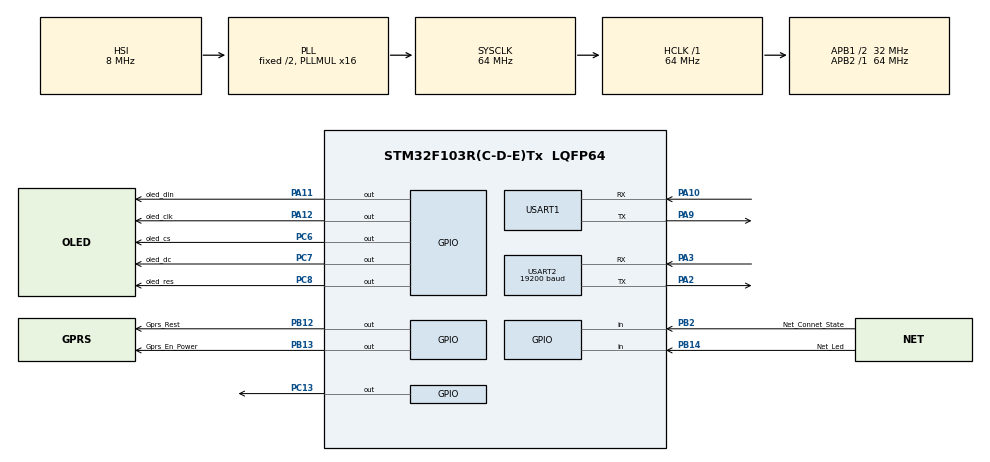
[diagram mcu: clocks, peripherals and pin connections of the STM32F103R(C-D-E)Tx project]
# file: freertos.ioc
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Dma.Request0=USART2_RX
Dma.Request1=USART2_TX
Dma.Request2=USART1_RX
Dma.Request3=USART1_TX
Dma.USART1_RX.2.Direction=DMA_PERIPH_TO_MEMORY
Dma.USART1_RX.2.Instance=DMA1_Channel5
Dma.USART1_RX.2.MemDataAlignment=DMA_MDATAALIGN_BYTE
Dma.USART1_RX.2.MemInc=DMA_MINC_ENABLE
Dma.USART1_RX.2.Mode=DMA_CIRCULAR
Dma.USART1_RX.2.PeriphDataAlignment=DMA_PDATAALIGN_BYTE
Dma.USART1_RX.2.PeriphInc=DMA_PINC_DISABLE
Dma.USART1_RX.2.Priority=DMA_PRIORITY_LOW
Dma.USART1_TX.3.Direction=DMA_MEMORY_TO_PERIPH
Dma.USART1_TX.3.Instance=DMA1_Channel4
Dma.USART1_TX.3.MemDataAlignment=DMA_MDATAALIGN_BYTE
Dma.USART1_TX.3.MemInc=DMA_MINC_ENABLE
Dma.USART1_TX.3.Mode=DMA_NORMAL
Dma.USART1_TX.3.PeriphDataAlignment=DMA_PDATAALIGN_BYTE
Dma.USART1_TX.3.PeriphInc=DMA_PINC_DISABLE
Dma.USART1_TX.3.Priority=DMA_PRIORITY_LOW
Dma.USART2_RX.0.Direction=DMA_PERIPH_TO_MEMORY
Dma.USART2_RX.0.Instance=DMA1_Channel6
Dma.USART2_RX.0.MemDataAlignment=DMA_MDATAALIGN_BYTE
Dma.USART2_RX.0.MemInc=DMA_MINC_ENABLE
Dma.USART2_RX.0.Mode=DMA_CIRCULAR
Dma.USART2_RX.0.PeriphDataAlignment=DMA_PDATAALIGN_BYTE
Dma.USART2_RX.0.PeriphInc=DMA_PINC_DISABLE
Dma.USART2_RX.0.Priority=DMA_PRIORITY_LOW
Dma.USART2_TX.1.Direction=DMA_MEMORY_TO_PERIPH
Dma.USART2_TX.1.Instance=DMA1_Channel7
Dma.USART2_TX.1.MemDataAlignment=DMA_MDATAALIGN_BYTE
Dma.USART2_TX.1.MemInc=DMA_MINC_ENABLE
Dma.USART2_TX.1.Mode=DMA_NORMAL
Dma.USART2_TX.1.PeriphDataAlignment=DMA_PDATAALIGN_BYTE
Dma.USART2_TX.1.PeriphInc=DMA_PINC_DISABLE
Dma.USART2_TX.1.Priority=DMA_PRIORITY_LOW
FREERTOS.Queues01=myQueue01,16,uint16_t,NULL,Dynamic,NULL,NULL
FREERTOS.Tasks01=defaultTask,0,128,StartDefaultTask,Default,NULL,Dynamic,NULL,NULL
FREERTOS.Timers01=myTimer01,Callback01,osTimerPeriodic,Default,NULL,Dynamic,NULL
FREERTOS.configUSE_TIMERS=1
Mcu.Family=STM32F1
Mcu.Name=STM32F103R(C-D-E)Tx
Mcu.Package=LQFP64
NVIC.DMA1_Channel4_IRQn=true\:5\:0\:false\:false\:true\:true
NVIC.DMA1_Channel5_IRQn=true\:5\:0\:false\:false\:true\:true
NVIC.DMA1_Channel6_IRQn=true\:5\:0\:true\:false\:true\:true
NVIC.DMA1_Channel7_IRQn=true\:5\:0\:true\:false\:true\:true
NVIC.PriorityGroup=NVIC_PRIORITYGROUP_4
NVIC.USART1_IRQn=true\:5\:0\:false\:false\:true\:true
NVIC.USART2_IRQn=true\:5\:0\:false\:false\:true\:true
PA10.Mode=Asynchronous
PA10.Signal=USART1_RX
PA11.GPIO_Label=oled_din
PA11.Signal=GPIO_Output
PA12.GPIO_Label=oled_clk
PA12.Signal=GPIO_Output
PA13.Mode=Serial_Wire
PA13.Signal=SYS_JTMS-SWDIO
PA14.Mode=Serial_Wire
PA14.Signal=SYS_JTCK-SWCLK
PA2.Mode=Asynchronous
PA2.Signal=USART2_TX
PA3.Mode=Asynchronous
PA3.Signal=USART2_RX
PA9.Mode=Asynchronous
PA9.Signal=USART1_TX
PB12.GPIO_Label=Gprs_Rest
PB12.Signal=GPIO_Output
PB13.GPIO_Label=Gprs_En_Power
PB13.Signal=GPIO_Output
PB14.GPIO_Label=Net_Led
PB14.GPIO_PuPd=GPIO_PULLUP
PB14.Signal=GPIO_Input
PB2.GPIO_Label=Net_Connet_State
PB2.Signal=GPIO_Input
PC13-TAMPER-RTC.Signal=GPIO_Output
PC6.GPIO_Label=oled_cs
PC6.PinState=GPIO_PIN_SET
PC6.Signal=GPIO_Output
PC7.GPIO_Label=oled_dc
PC7.Signal=GPIO_Output
PC8.GPIO_Label=oled_res
PC8.Signal=GPIO_Output
ProjectManager.HeapSize=0x200
ProjectManager.StackSize=0x400
ProjectManager.TargetToolchain=MDK-ARM V5
RCC.AHBFreq_Value=64000000
RCC.APB1CLKDivider=RCC_HCLK_DIV2
RCC.APB1Freq_Value=32000000
RCC.APB1TimFreq_Value=64000000
RCC.APB2Freq_Value=64000000
RCC.APB2TimFreq_Value=64000000
RCC.HCLKFreq_Value=64000000
RCC.PLLMUL=RCC_PLL_MUL16
RCC.SYSCLKFreq_VALUE=64000000
RCC.SYSCLKSource=RCC_SYSCLKSOURCE_PLLCLK
RCC.USBFreq_Value=64000000
USART1.VirtualMode=VM_ASYNC
USART2.BaudRate=19200
USART2.VirtualMode=VM_ASYNC
VP_FREERTOS_VS_ENABLE.Mode=Enabled
board=freertos

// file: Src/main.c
/**
  ******************************************************************************
  * File Name          : main.c
  * Description        : Main program body
  ******************************************************************************
  * This notice applies to any and all portions of this file
  * that are not between comment pairs USER CODE BEGIN and
  * USER CODE END. Other portions of this file, whether
  * inserted by the user or by software development tools
  * are owned by their respective copyright owners.
  *
  * Copyright (c) 2017 STMicroelectronics International N.V.
  * All rights reserved.
  *
  * Redistribution and use in source and binary forms, with or without
  * modification, are permitted, provided that the following conditions are met:
  *
  * 1. Redistribution of source code must retain the above copyright notice,
  *    this list of conditions and the following disclaimer.
  * 2. Redistributions in binary form must reproduce the above copyright notice,
  *    this list of conditions and the following disclaimer in the documentation
  *    and/or other materials provided with the distribution.
  * 3. Neither the name of STMicroelectronics nor the names of other
  *    contributors to this software may be used to endorse or promote products
  *    derived from this software without specific written permission.
  * 4. This software, including modifications and/or derivative works of this
  *    software, must execute solely and exclusively on microcontroller or
  *    microprocessor devices manufactured by or for STMicroelectronics.
  * 5. Redistribution and use of this software other than as permitted under
  *    this license is void and will automatically terminate your rights under
  *    this license.
  *
  * THIS SOFTWARE IS PROVIDED BY STMICROELECTRONICS AND CONTRIBUTORS "AS IS"
  * AND ANY EXPRESS, IMPLIED OR STATUTORY WARRANTIES, INCLUDING, BUT NOT
  * LIMITED TO, THE IMPLIED WARRANTIES OF MERCHANTABILITY, FITNESS FOR A
  * PARTICULAR PURPOSE AND NON-INFRINGEMENT OF THIRD PARTY INTELLECTUAL PROPERTY
  * RIGHTS ARE DISCLAIMED TO THE FULLEST EXTENT PERMITTED BY LAW. IN NO EVENT
  * SHALL STMICROELECTRONICS OR CONTRIBUTORS BE LIABLE FOR ANY DIRECT, INDIRECT,
  * INCIDENTAL, SPECIAL, EXEMPLARY, OR CONSEQUENTIAL DAMAGES (INCLUDING, BUT NOT
  * LIMITED TO, PROCUREMENT OF SUBSTITUTE GOODS OR SERVICES; LOSS OF USE, DATA,
  * OR PROFITS; OR BUSINESS INTERRUPTION) HOWEVER CAUSED AND ON ANY THEORY OF
  * LIABILITY, WHETHER IN CONTRACT, STRICT LIABILITY, OR TORT (INCLUDING
  * NEGLIGENCE OR OTHERWISE) ARISING IN ANY WAY OUT OF THE USE OF THIS SOFTWARE,
  * EVEN IF ADVISED OF THE POSSIBILITY OF SUCH DAMAGE.
  *
  ******************************************************************************
  */
#include "main.h"
#include "stm32f1xx_hal.h"
#include "cmsis_os.h"

/* USER CODE BEGIN Includes */
#include "oled.h"
#include "gprs.h"
/* USER CODE END Includes */

UART_HandleTypeDef huart1;
UART_HandleTypeDef huart2;
DMA_HandleTypeDef hdma_usart1_rx;
DMA_HandleTypeDef hdma_usart1_tx;
DMA_HandleTypeDef hdma_usart2_rx;
DMA_HandleTypeDef hdma_usart2_tx;

osThreadId defaultTaskHandle;
osMessageQId myQueue01Handle;
osTimerId myTimer01Handle;

/* USER CODE BEGIN PV */
/* Private variables ---------------------------------------------------------*/
#define MAXSIZE 100
uint8_t arev_zigbee[1];
uint8_t arev_mqtt[1];
uint8_t RX_DATA[MAXSIZE]={0};
/* USER CODE END PV */

void SystemClock_Config(void);
static void MX_GPIO_Init(void);
static void MX_DMA_Init(void);
static void MX_USART2_UART_Init(void);
static void MX_USART1_UART_Init(void);
void StartDefaultTask(void const * argument);
void Callback01(void const * argument);

/* USER CODE BEGIN PFP */
/* Private function prototypes -----------------------------------------------*/

/* USER CODE END PFP */

int main(void)
{

  /* MCU Configuration----------------------------------------------------------*/

  /* Reset of all peripherals, Initializes the Flash interface and the Systick. */
  HAL_Init();

  /* Configure the system clock */
  SystemClock_Config();

  /* Initialize all configured peripherals */
  MX_GPIO_Init();
  MX_DMA_Init();
  MX_USART2_UART_Init();
  MX_USART1_UART_Init();

  /* USER CODE BEGIN 2 */
//	u8 test1[10]="haoren\r\n";
	OLED_Init();
	init_gprs();
	HAL_UART_Receive_DMA(&huart2, arev_zigbee, 1);
	HAL_UART_Receive_DMA(&huart1,RX_DATA,MAXSIZE);
	__HAL_UART_ENABLE_IT(&huart1,UART_IT_IDLE);
  //HAL_UART_Transmit_DMA(&huart1 , (u8*)"AT\r\n" ,4);
  /* USER CODE END 2 */

  /* Create the timer(s) */
  /* definition and creation of myTimer01 */
  osTimerDef(myTimer01, Callback01);
  myTimer01Handle = osTimerCreate(osTimer(myTimer01), osTimerPeriodic, NULL);

  /* Create the thread(s) */
  /* definition and creation of defaultTask */
  osThreadDef(defaultTask, StartDefaultTask, osPriorityNormal, 0, 128);
  defaultTaskHandle = osThreadCreate(osThread(defaultTask), NULL);

  /* Create the queue(s) */
  /* definition and creation of myQueue01 */
  osMessageQDef(myQueue01, 16, uint16_t);
  myQueue01Handle = osMessageCreate(osMessageQ(myQueue01), NULL);

  /* USER CODE BEGIN RTOS_QUEUES */
  /* add queues, ... */
	osTimerStart(myTimer01Handle,1000);
  /* USER CODE END RTOS_QUEUES */

  /* Start scheduler */
  osKernelStart();

  /* We should never get here as control is now taken by the scheduler */

  /* Infinite loop */

  while (1)
  {

  }

}

/** System Clock Configuration
*/
void SystemClock_Config(void)
{

  RCC_OscInitTypeDef RCC_OscInitStruct;
  RCC_ClkInitTypeDef RCC_ClkInitStruct;

    /**Initializes the CPU, AHB and APB busses clocks
    */
  RCC_OscInitStruct.OscillatorType = RCC_OSCILLATORTYPE_HSI;
  RCC_OscInitStruct.HSIState = RCC_HSI_ON;
  RCC_OscInitStruct.HSICalibrationValue = 16;
  RCC_OscInitStruct.PLL.PLLState = RCC_PLL_ON;
  RCC_OscInitStruct.PLL.PLLSource = RCC_PLLSOURCE_HSI_DIV2;
  RCC_OscInitStruct.PLL.PLLMUL = RCC_PLL_MUL16;
  if (HAL_RCC_OscConfig(&RCC_OscInitStruct) != HAL_OK)
  {
    _Error_Handler(__FILE__, __LINE__);
  }

    /**Initializes the CPU, AHB and APB busses clocks
    */
  RCC_ClkInitStruct.ClockType = RCC_CLOCKTYPE_HCLK|RCC_CLOCKTYPE_SYSCLK
                              |RCC_CLOCKTYPE_PCLK1|RCC_CLOCKTYPE_PCLK2;
  RCC_ClkInitStruct.SYSCLKSource = RCC_SYSCLKSOURCE_PLLCLK;
  RCC_ClkInitStruct.AHBCLKDivider = RCC_SYSCLK_DIV1;
  RCC_ClkInitStruct.APB1CLKDivider = RCC_HCLK_DIV2;
  RCC_ClkInitStruct.APB2CLKDivider = RCC_HCLK_DIV1;

  if (HAL_RCC_ClockConfig(&RCC_ClkInitStruct, FLASH_LATENCY_2) != HAL_OK)
  {
    _Error_Handler(__FILE__, __LINE__);
  }

    /**Configure the Systick interrupt time
    */
  HAL_SYSTICK_Config(HAL_RCC_GetHCLKFreq()/1000);

    /**Configure the Systick
    */
  HAL_SYSTICK_CLKSourceConfig(SYSTICK_CLKSOURCE_HCLK);

  /* SysTick_IRQn interrupt configuration */
  HAL_NVIC_SetPriority(SysTick_IRQn, 15, 0);
}

/* USART1 init function */
static void MX_USART1_UART_Init(void)
{

  huart1.Instance = USART1;
  huart1.Init.BaudRate = 115200;
  huart1.Init.WordLength = UART_WORDLENGTH_8B;
  huart1.Init.StopBits = UART_STOPBITS_1;
  huart1.Init.Parity = UART_PARITY_NONE;
  huart1.Init.Mode = UART_MODE_TX_RX;
  huart1.Init.HwFlowCtl = UART_HWCONTROL_NONE;
  huart1.Init.OverSampling = UART_OVERSAMPLING_16;
  if (HAL_UART_Init(&huart1) != HAL_OK)
  {
    _Error_Handler(__FILE__, __LINE__);
  }

}

/* USART2 init function */
static void MX_USART2_UART_Init(void)
{

  huart2.Instance = USART2;
  huart2.Init.BaudRate = 19200;
  huart2.Init.WordLength = UART_WORDLENGTH_8B;
  huart2.Init.StopBits = UART_STOPBITS_1;
  huart2.Init.Parity = UART_PARITY_NONE;
  huart2.Init.Mode = UART_MODE_TX_RX;
  huart2.Init.HwFlowCtl = UART_HWCONTROL_NONE;
  huart2.Init.OverSampling = UART_OVERSAMPLING_16;
  if (HAL_UART_Init(&huart2) != HAL_OK)
  {
    _Error_Handler(__FILE__, __LINE__);
  }

}

static void MX_DMA_Init(void)
{
  /* DMA controller clock enable */
  __HAL_RCC_DMA1_CLK_ENABLE();

  /* DMA interrupt init */
  /* DMA1_Channel4_IRQn interrupt configuration */
  HAL_NVIC_SetPriority(DMA1_Channel4_IRQn, 5, 0);
  HAL_NVIC_EnableIRQ(DMA1_Channel4_IRQn);
  /* DMA1_Channel5_IRQn interrupt configuration */
  HAL_NVIC_SetPriority(DMA1_Channel5_IRQn, 5, 0);
  HAL_NVIC_EnableIRQ(DMA1_Channel5_IRQn);
  /* DMA1_Channel6_IRQn interrupt configuration */
  HAL_NVIC_SetPriority(DMA1_Channel6_IRQn, 5, 0);
  HAL_NVIC_EnableIRQ(DMA1_Channel6_IRQn);
  /* DMA1_Channel7_IRQn interrupt configuration */
  HAL_NVIC_SetPriority(DMA1_Channel7_IRQn, 5, 0);
  HAL_NVIC_EnableIRQ(DMA1_Channel7_IRQn);

}

/** Configure pins as
        * Analog
        * Input
        * Output
        * EVENT_OUT
        * EXTI
*/
static void MX_GPIO_Init(void)
{

  GPIO_InitTypeDef GPIO_InitStruct;

  /* GPIO Ports Clock Enable */
  __HAL_RCC_GPIOC_CLK_ENABLE();
  __HAL_RCC_GPIOA_CLK_ENABLE();
  __HAL_RCC_GPIOB_CLK_ENABLE();

  /*Configure GPIO pin Output Level */
  HAL_GPIO_WritePin(GPIOC, GPIO_PIN_13|oled_dc_Pin|oled_res_Pin, GPIO_PIN_RESET);

  /*Configure GPIO pin Output Level */
  HAL_GPIO_WritePin(GPIOB, Gprs_Rest_Pin|Gprs_En_Power_Pin, GPIO_PIN_RESET);

  /*Configure GPIO pin Output Level */
  HAL_GPIO_WritePin(oled_cs_GPIO_Port, oled_cs_Pin, GPIO_PIN_SET);

  /*Configure GPIO pin Output Level */
  HAL_GPIO_WritePin(GPIOA, oled_din_Pin|oled_clk_Pin, GPIO_PIN_RESET);

  /*Configure GPIO pins : PC13 oled_cs_Pin oled_dc_Pin oled_res_Pin */
  GPIO_InitStruct.Pin = GPIO_PIN_13|oled_cs_Pin|oled_dc_Pin|oled_res_Pin;
  GPIO_InitStruct.Mode = GPIO_MODE_OUTPUT_PP;
  GPIO_InitStruct.Speed = GPIO_SPEED_FREQ_LOW;
  HAL_GPIO_Init(GPIOC, &GPIO_InitStruct);

  /*Configure GPIO pin : Net_Connet_State_Pin */
  GPIO_InitStruct.Pin = Net_Connet_State_Pin;
  GPIO_InitStruct.Mode = GPIO_MODE_INPUT;
  GPIO_InitStruct.Pull = GPIO_NOPULL;
  HAL_GPIO_Init(Net_Connet_State_GPIO_Port, &GPIO_InitStruct);

  /*Configure GPIO pins : Gprs_Rest_Pin Gprs_En_Power_Pin */
  GPIO_InitStruct.Pin = Gprs_Rest_Pin|Gprs_En_Power_Pin;
  GPIO_InitStruct.Mode = GPIO_MODE_OUTPUT_PP;
  GPIO_InitStruct.Speed = GPIO_SPEED_FREQ_LOW;
  HAL_GPIO_Init(GPIOB, &GPIO_InitStruct);

  /*Configure GPIO pin : Net_Led_Pin */
  GPIO_InitStruct.Pin = Net_Led_Pin;
  GPIO_InitStruct.Mode = GPIO_MODE_INPUT;
  GPIO_InitStruct.Pull = GPIO_PULLUP;
  HAL_GPIO_Init(Net_Led_GPIO_Port, &GPIO_InitStruct);

  /*Configure GPIO pins : oled_din_Pin oled_clk_Pin */
  GPIO_InitStruct.Pin = oled_din_Pin|oled_clk_Pin;
  GPIO_InitStruct.Mode = GPIO_MODE_OUTPUT_PP;
  GPIO_InitStruct.Speed = GPIO_SPEED_FREQ_LOW;
  HAL_GPIO_Init(GPIOA, &GPIO_InitStruct);

}

/* StartDefaultTask function */
void StartDefaultTask(void const * argument)
{

  /* USER CODE BEGIN 5 */
  /* Infinite loop */
  for(;;)
  {
//		HAL_GPIO_TogglePin(GPIOC, GPIO_PIN_13);
//		//HAL_UART_Transmit(&huart2 ,(u8*)"haoren\r\n",8,100);
//		HAL_UART_Transmit_DMA(&huart2 , (u8*)"12345678\r\n" ,10);
//		//HAL_Delay(1000);
//		OLED_ShowString(0,0,(u8 *)"1234567890");
		//HAL_UART_Tra

		//HAL_UART_Transmit_DMA(&huart2 , (u8*)"haoren\r\n" , 8);
		//HAL_UART_Transmit

    osDelay(1000);
  }
  /* USER CODE END 5 */
}

/* Callback01 function */
void Callback01(void const * argument)
{
  /* USER CODE BEGIN Callback01 */
  OLED_ShowString(0,0,(u8 *)"12345678");
	//HAL_GPIO_TogglePin(GPIOC, GPIO_PIN_13);
  /* USER CODE END Callback01 */
}

void _Error_Handler(char * file, int line)
{
  while(1)
  {
  }
}

/************************ (C) COPYRIGHT STMicroelectronics *****END OF FILE****/
